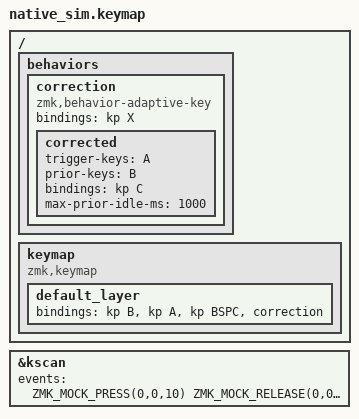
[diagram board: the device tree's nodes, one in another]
#include <behaviors.dtsi>
#include <dt-bindings/zmk/keys.h>
#include <dt-bindings/zmk/kscan_mock.h>

/ {
    behaviors {
        correction: correction {
            compatible = "zmk,behavior-adaptive-key";
            #binding-cells = <0>;
            bindings = <&kp X>;

            corrected {
                trigger-keys = <A>;
                prior-keys = <B>;
                bindings = <&kp C>;
                max-prior-idle-ms = <1000>;
            };
        };
    };

    keymap {
        compatible = "zmk,keymap";

        default_layer {
            bindings = <&kp B &kp A &kp BSPC &correction>;
        };
    };
};

&kscan {
    events = <
        ZMK_MOCK_PRESS(0,0,10)
        ZMK_MOCK_RELEASE(0,0,10)
        ZMK_MOCK_PRESS(0,1,10)
        ZMK_MOCK_RELEASE(0,1,10)
        ZMK_MOCK_PRESS(0,0,10)
        ZMK_MOCK_RELEASE(0,0,1200)
        ZMK_MOCK_PRESS(1,0,10)
        ZMK_MOCK_RELEASE(1,0,500)
        ZMK_MOCK_PRESS(1,1,10)
        ZMK_MOCK_RELEASE(1,1,10)
    >;
};
